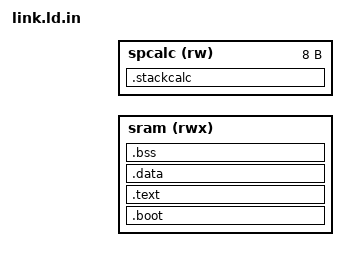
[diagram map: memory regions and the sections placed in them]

MEMORY 
{ 
  sram (rwx) : ORIGIN = @MAIN_MEMORY_BASE@, LENGTH = @MAIN_MEMORY_SIZE_B@ - 8
  spcalc(rw) : ORIGIN = @MAIN_MEMORY_BASE@ + @MAIN_MEMORY_SIZE_B@ - 8, LENGTH = 8
}

ENTRY(__start)

SECTIONS
{
  .boot :
  {
      PROVIDE(_text_start = .);
      KEEP(*(.boot.*))	         /* boot code */
  } > sram

  .text :
  {
    . = ALIGN(4);
    *(.text .text.*)		 /* remaining code */
    *(.rodata)			 /* read-only data (constants) */
    *(.rodata*)
    *(.rdata*)
    . = ALIGN(4);
    PROVIDE(_text_end = .);
  } > sram
  
  .data : 
  {   
    . = ALIGN(4);
    _data_start = .;
    
    *(.got.plt) *(.got)
    *(.shdata)
    *(.data .data.* .gnu.linkonce.d.*)
    . = ALIGN(16);
    . = ALIGN (8);
    *(.ram)
    *(.eh_frame)
    . = ALIGN (8);
    _edata = .;
    _data_end = .;
  } > sram
   
  .bss : 
  {
    . = ALIGN(4);
    PROVIDE(_bss_start = .);
    *(.bss*)
    *(COMMON)
    . = ALIGN(4);
    PROVIDE(_bss_end = .);
    . += 8;

    __heap_start__ = .;
    end = __heap_start__;
    _end = end;
    __end = end;
    KEEP(*(.heap))
    __heap_end__ = .;
    __HeapLimit = __heap_end__;
  } > sram

  .stackcalc :
  {
    PROVIDE(_sp = .);
    LONG(0xDEADBEAF);
  } > spcalc
}
